AUTOSAR XML (schema 3-2-1)
package /SeatHeater
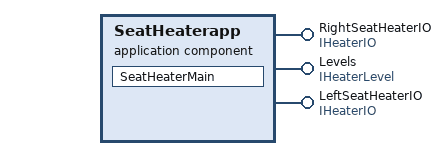
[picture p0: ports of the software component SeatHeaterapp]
  application software component type SeatHeaterapp
    provide port RightSeatHeaterIO: provided-interface=IHeaterIO
    provide port Levels: provided-interface=IHeaterLevel
    provide port LeftSeatHeaterIO: provided-interface=IHeaterIO
  swc implementation SeatHeaterImplementation: behavior=SeatHeaterBehavior
  internal behavior SeatHeaterBehavior: component=SeatHeaterapp
    operation invoked event opInvokedEventSeatHeater: start-on-event=SeatHeaterMain, operation=Levels.SetHeat
    runnable SeatHeaterMain: can-be-invoked-concurrently=true
      data write access dataWriteAccess_1: data-element=LeftSeatHeaterIO.HeaterValue
      data write access dataWriteAccess_2: data-element=RightSeatHeaterIO.HeaterValue
